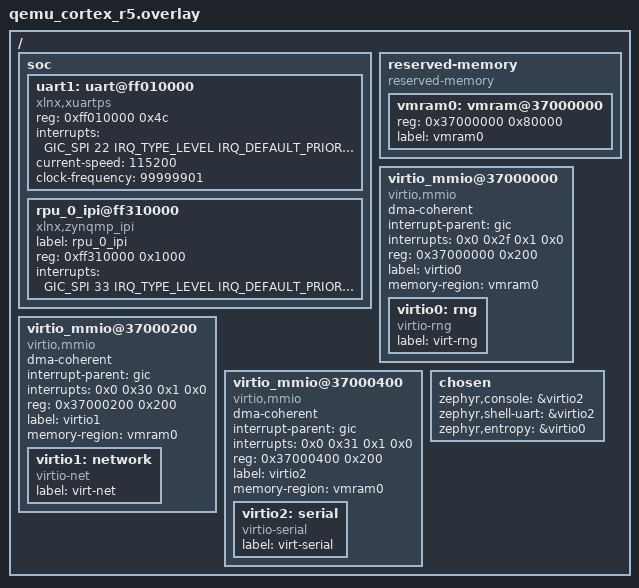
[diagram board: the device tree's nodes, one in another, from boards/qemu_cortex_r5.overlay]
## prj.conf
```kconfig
CONFIG_ASSERT=y
CONFIG_VIRTIO=y
CONFIG_VIRTIO_MMIO=y
CONFIG_VIRTIO_NETWORK=y
CONFIG_VIRTIO_RNG=y
CONFIG_ENTROPY_GENERATOR=y

CONFIG_EARLY_CONSOLE=y
CONFIG_SERIAL_INIT_PRIORITY=45
CONFIG_CONSOLE_INIT_PRIORITY=46

CONFIG_SHELL=y
CONFIG_NET_SHELL=y

CONFIG_NET_L2_ETHERNET=y
CONFIG_NET_DRIVERS=y
CONFIG_NETWORKING=y
CONFIG_NET_IPV6=n
CONFIG_NET_IPV4=y
CONFIG_NET_CONFIG_NEED_IPV4=y
CONFIG_NET_DHCPV4=y

CONFIG_COMPILER_OPT=" -DHVL_VIRTIO"
CONFIG_HAVE_CUSTOM_LINKER_SCRIPT=y
CONFIG_CUSTOM_LINKER_SCRIPT="linker_r5_hvl.ld"

CONFIG_OPENAMP=y
CONFIG_LIBMETAL=y
CONFIG_HEAP_MEM_POOL_SIZE=131072

CONFIG_VIRTIO_SERIAL=y
CONFIG_BOOT_BANNER=n
CONFIG_UART_INTERRUPT_DRIVEN=n
CONFIG_SHELL_BACKEND_SERIAL_INTERRUPT_DRIVEN=n
CONFIG_SHELL_BACKEND_SERIAL_INIT_PRIORITY=0
```

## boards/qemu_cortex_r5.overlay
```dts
/{

	soc {
		uart1: uart@ff010000 {
			compatible = "xlnx,xuartps";
			reg = <0xff010000 0x4c>;
			status = "disabled";
			interrupts = <GIC_SPI 22 IRQ_TYPE_LEVEL
					IRQ_DEFAULT_PRIORITY>;
			interrupt-names = "irq_1";
		};
		rpu_0_ipi@ff310000 {
			compatible = "xlnx,zynqmp_ipi";
			label = "rpu_0_ipi";
			reg = < 0xff310000 0x1000 >;
			interrupts = < GIC_SPI 33 IRQ_TYPE_LEVEL
						IRQ_DEFAULT_PRIORITY>;
			status = "okay";
		};
	};
	reserved-memory {
		compatible = "reserved-memory";
		#address-cells = <1>;
		#size-cells = <1>;
		status = "okay";
		ranges;

		vmram0: vmram@37000000 {
			status = "okay";
			reg = < 0x37000000 0x80000 >;
			device_type = "memory";
			label = "vmram0";
		};
	};
	virtio_mmio@37000000 {
		dma-coherent;
		interrupt-parent = < &gic >;
		interrupts = < 0x0 0x2f 0x1 0x0 >;
		reg = < 0x37000000 0x200 >;
		compatible = "virtio,mmio";
		status = "okay";
		label = "virtio0";
		memory-region = < &vmram0 >;
		virtio0: rng {
			label = "virt-rng";
			compatible = "virtio-rng";
		};
	};
	virtio_mmio@37000200 {
		dma-coherent;
		interrupt-parent = < &gic >;
		interrupts = < 0x0 0x30 0x1 0x0 >;
		reg = < 0x37000200 0x200 >;
		compatible = "virtio,mmio";
		status = "okay";
		label = "virtio1";
		memory-region = < &vmram0 >;
		virtio1: network {
			label = "virt-net";
			compatible = "virtio-net";
		};
	};
	virtio_mmio@37000400 {
		dma-coherent;
		interrupt-parent = < &gic >;
		interrupts = < 0x0 0x31 0x1 0x0 >;
		reg = < 0x37000400 0x200 >;
		compatible = "virtio,mmio";
		status = "okay";
		label = "virtio2";
		memory-region = < &vmram0 >;
		virtio2: serial {
			label = "virt-serial";
			compatible = "virtio-serial";
		};
	};
	chosen {
		zephyr,console = &virtio2;
		zephyr,shell-uart = &virtio2;
		zephyr,entropy = &virtio0;
	};
};

&uart1 {
	status = "okay";
	current-speed = <115200>;
	clock-frequency = <99999901>;
};

/delete-node/ &uart0;
/delete-node/ &gem0;
/delete-node/ &gem1;
/delete-node/ &gem2;
/delete-node/ &gem3;
```

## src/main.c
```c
/*
 * Copyright (c) 2012-2024 Wind River Systems, Inc.
 *
 * SPDX-License-Identifier: Apache-2.0
 */

#include <zephyr/kernel.h>
#include <zephyr/sys/printk.h>
#include <zephyr/init.h>
#include <zephyr/net/net_if.h>
#include <zephyr/net/net_core.h>
#include <zephyr/net/net_ip.h>
#include <zephyr/net/net_mgmt.h>
#include <zephyr/drivers/entropy.h>

#define BUFFER_LENGTH 10
#define RECHECK_RANDOM_ENTROPY 0x10

extern char *net_sprint_addr(sa_family_t af, const void *addr);

#ifdef CONFIG_ENTROPY_GENERATOR
static int random_entropy(const struct device *dev, char *buffer, char num)
{
	int ret, i;
	int count = 0;

	(void)memset(buffer, num, BUFFER_LENGTH);

	/* The BUFFER_LENGTH-1 is used so the driver will not
	 * write the last byte of the buffer. If that last
	 * byte is not 0 on return it means the driver wrote
	 * outside the passed buffer, and that should never
	 * happen.
	 */
	ret = entropy_get_entropy(dev, buffer, BUFFER_LENGTH - 1);
	if (ret) {
		printk("Error: entropy_get_entropy failed: %d\n", ret);
		return -1;
	}

	if (buffer[BUFFER_LENGTH - 1] != num) {
		printk("Error: entropy_get_entropy buffer overflow\n");
		return -1;
	}

	for (i = 0; i < BUFFER_LENGTH - 1; i++) {
		printk("  0x%02x\n", buffer[i]);
		if (buffer[i] == num) {
			count++;
		}
	}

	if (count >= 2) {
		return RECHECK_RANDOM_ENTROPY;
	} else {
		return 0;
	}
}

/*
 * Function invokes the get_entropy callback in driver
 * to get the random data and fill to passed buffer
 */
static int get_entropy(void)
{
	const struct device *const dev = DEVICE_DT_GET(DT_CHOSEN(zephyr_entropy));
	uint8_t buffer[BUFFER_LENGTH] = { 0 };
	int ret;

	if (!device_is_ready(dev)) {
		printk("error: random device not ready\n");
		return -1;
	}

	printk("random device is %p, name is %s\n",
		 dev, dev->name);

	ret = random_entropy(dev, buffer, 0);

	/* Check whether 20% or more of buffer still filled with default
	 * value(0), if yes then recheck again by filling nonzero value(0xa5)
	 * to buffer. Recheck random_entropy and verify whether 20% or more
	 * of buffer filled with value(0xa5) or not.
	 */
	if (ret == RECHECK_RANDOM_ENTROPY) {
		ret = random_entropy(dev, buffer, 0xa5);
		if (ret == RECHECK_RANDOM_ENTROPY) {
			return -1;
		} else {
			return ret;
		}
	}
	return ret;
}
#endif

extern uint32_t __shmem0_pool_start;
extern uint32_t __shmem0_end;

int main(void)
{
	printk("Board: %s\n", CONFIG_BOARD);

#ifdef CONFIG_ENTROPY_GENERATOR
	//rng
	printk("%s:%d - get_entropy test %s\n", __FUNCTION__, __LINE__,
		(get_entropy() != 0) ? "failed" : "passed");
#endif

#ifdef CONFIG_NETWORKING
	//net
	struct net_if *iface;

	iface = net_if_get_default();

	struct in_addr my_addr2 = { { { 192, 168, 200, 2 } } };
	struct in_addr my_mask2 = { { { 255, 255, 255, 0 } } };
	struct net_if_addr *ifaddr;
	ifaddr = net_if_ipv4_addr_add(iface, &my_addr2, NET_ADDR_MANUAL, 0);
	if (!ifaddr) {
		printk("Cannot add IPv4 address %s\n", net_sprint_addr(AF_INET, &my_addr2));
		return -1;
    }
	net_if_ipv4_set_netmask_by_addr(iface, &my_addr2, &my_mask2);

	//ifaddr->addr_state = NET_ADDR_PREFERRED;
	net_if_up(iface);
#endif

	return 0;
}
```

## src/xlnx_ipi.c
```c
/*
 * Copyright (c) 2021-2024 Wind River Systems, Inc.
 *
 * SPDX-License-Identifier: Apache-2.0
 *
 */

#include <zephyr/devicetree.h>
#include <zephyr/device.h>
#include <zephyr/sys/mutex.h>
#include <openamp/virtio_mmio.h>
#include <openamp/virtio_mmio_hvl.h>
#include <stdio.h>
#include <string.h>

#define DT_DRV_COMPAT xlnx_zynqmp_ipi

/* Register offsets */
#define IPI_TRIG    0x00
#define IPI_OBS     0x04
#define IPI_ISR     0x10
#define IPI_IMR     0x14
#define IPI_IER     0x18
#define IPI_IDR     0x1C

#define READ32(dev, offset) sys_read32(DEVICE_MMIO_GET(dev) + offset)
#define WRITE32(dev, offset, val) sys_write32(val, DEVICE_MMIO_GET(dev) + offset)
#define HVL_CFG_ACK 0xAABBAABB

struct xlnx_ipi_config {
    DEVICE_MMIO_ROM;
    void (*irq_config)(const struct device *dev);
};

static int xlnx_ipi_init(const struct device *dev);
static void xlnx_ipi_isr(const struct device *dev);

static int xlnx_ipi_init(const struct device *dev)
{
    DEVICE_MMIO_MAP(dev, K_MEM_CACHE_NONE);

    WRITE32(dev, IPI_IDR, 0xFFFFFFFF);
    WRITE32(dev, IPI_ISR, 0xFFFFFFFF);
    ((struct xlnx_ipi_config *)dev->config)->irq_config(dev);

    WRITE32(dev, IPI_IER, (1 << 24));
    return 0;
}

static void xlnx_ipi_isr(const struct device *dev)
{
    uint32_t isr, imr;
    uint32_t i;

    isr = READ32(dev, IPI_ISR);
    imr = READ32(dev, IPI_IMR);

    for (i = 0 ; i < 32; i++)
    {
        if (imr & (1 << i)) /* masked */
            continue;
        if (!(isr & (1 << i))) /* not active */
            continue;
        /* ACK interrupt */
        WRITE32(dev, IPI_ISR, (1 << i));
    }

#ifdef HVL_VIRTIO
    virtio_mmio_hvl_cb_run();
#endif
}

typedef void (*ipi_notify_t)(const struct device *dev);
__subsystem struct xlnx_ipi_api {
    ipi_notify_t notify;
};

static void xlnx_ipi_notify(const struct device *dev)
{
    WRITE32(dev, IPI_TRIG, (1 << 24));
}

static const struct xlnx_ipi_api xlnx_ipi_api = {
    .notify = xlnx_ipi_notify,
};

#define CREATE_XLNX_IPI_DEVICE(inst)                              \
    static void irq_config_##inst(const struct device *dev)          \
    {\
        IRQ_CONNECT(DT_INST_IRQ(inst, irq),\
                    DT_INST_IRQ(inst, priority),\
                    xlnx_ipi_isr,\
                    DEVICE_DT_INST_GET(inst),\
                    0);\
        irq_enable(DT_INST_IRQ(inst, irq)); \
    }\
    static struct xlnx_ipi_config xlnx_cfg_##inst = {      \
        DEVICE_MMIO_ROM_INIT(DT_DRV_INST(inst)),                     \
        irq_config_##inst,                                           \
    };                                                               \
    DEVICE_DT_INST_DEFINE(inst,                                      \
                          xlnx_ipi_init,                               \
                          NULL,                                      \
                          NULL,                                      \
                          &xlnx_cfg_##inst,                        \
                          PRE_KERNEL_1,               \
                          CONFIG_KERNEL_INIT_PRIORITY_DEVICE,        \
                          &xlnx_ipi_api);

DT_INST_FOREACH_STATUS_OKAY(CREATE_XLNX_IPI_DEVICE)

void virtio_mmio_hvl_ipi(void *param) {
	const struct device *dev = NULL;

    (void)param;

	dev = DEVICE_DT_GET_ANY(xlnx_zynqmp_ipi);
	((struct xlnx_ipi_api *)dev->api)->notify(dev);
}
```
